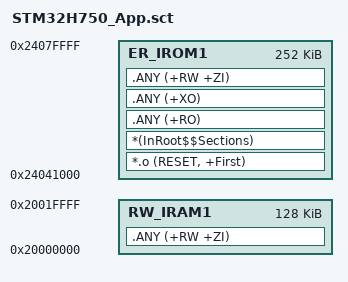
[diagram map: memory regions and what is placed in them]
; *************************************************************
; *** Scatter-Loading Description File generated by uVision ***
; *************************************************************

LR_IROM1 0x24041000 0x0003f000  {    ; load region size_region
  ER_IROM1 0x24041000 0x0003f000  {  ; load address = execution address
   *.o (RESET, +First)
   *(InRoot$$Sections)
   .ANY (+RO)
   .ANY (+XO)
   .ANY (+RW +ZI)
  }
  RW_IRAM1 0x20000000 0x00020000  {  ; RW data
   .ANY (+RW +ZI)
  }
}

